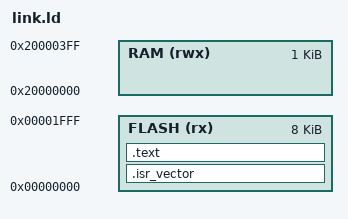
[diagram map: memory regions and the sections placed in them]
ENTRY(Reset_Handler)

MEMORY
{
  FLASH (rx) : ORIGIN = 0x00000000, LENGTH = 8K
  RAM   (rwx): ORIGIN = 0x20000000, LENGTH = 1K
}

__stack_top = ORIGIN(RAM) + LENGTH(RAM);

SECTIONS
{
  .isr_vector ORIGIN(FLASH) :
  {
    KEEP(*(.isr_vector))
  } > FLASH

  .text :
  {
    *(.text*)
    *(.rodata*)
    . = ALIGN(4);
  } > FLASH
}
